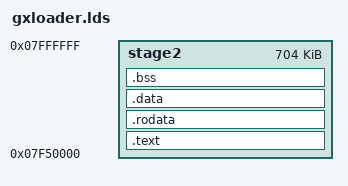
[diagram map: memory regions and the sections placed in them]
#include "version_autogenerated.h"

MEMORY
{
	stage2	:	ORIGIN = 0x07f50000,       	LENGTH = 0xb0000
}

ENTRY(ResetEntry)
SECTIONS {
	. = ALIGN(2048);
	.text :
	{
		_stage2_start_ = .;
		_stage2_text_start_ = .;
		cpu/arm/vega/vega_start.o(.text*)
		cpu/arm/vega/vega_start.o(.rodata*)
		cpu/arm/vega/vega_start.o(.data*)
		*(.cache_section)
		*(.sram_text)
		*(.irq_text)
		. = ALIGN(512);
		*(.fiq_text)
		. = ALIGN(512);
		*(.entry_text)
		. = ALIGN(4);
		*(.text*)
		. = ALIGN(4);
		_stage2_text_end_ = .;
		__commands_begin = .;
		KEEP(*(.data.commands))
		. = ALIGN(4);
		__commands_end = .;
	} > stage2

	.rodata : { *(SORT_BY_ALIGNMENT(SORT_BY_NAME(.rodata*))) } > stage2

	. = ALIGN(2048);
	.data :
	{
		_stage2_data_start_ = .;
		*(.data*)
		. = ALIGN(16);
		_stage2_data_end_ = .;
	} > stage2
	
	. = ALIGN(4);
	.bss :
	{
		. = ALIGN(4);
		__bss_start__ = .;
		*(.bss*)
		*(COMMON)
		. = ALIGN(4);
		__bss_end__ = .;
	} > stage2

}

